# STM32H7S register map
File version: 1.3
CPU: CM7 r0p1, little endian, MPU, FPU, 4 interrupt priority bits
Registers are 32-bit, read-write, reset 0x0 unless marked. A register's access mark holds for its fields unless they carry their own. Offsets are from the block's base; [hi:lo] are bit positions; {n}, {i} and the like mark numbered series.

## GPIOA — General-purpose I/Os
Base 0x58020000
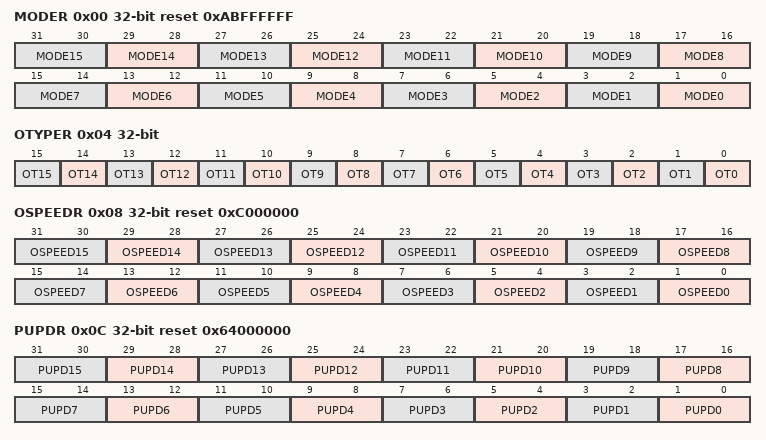
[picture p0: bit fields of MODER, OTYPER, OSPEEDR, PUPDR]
0x00 MODER reset 0xABFFFFFF — GPIO port mode register
  [2n+1:2n] MODE{n} (n=0..15) — Port x configuration pin {n}
    0=Input mode; 1=Output (General purpose output mode); 2=Alternate function mode; 3=Analog mode
0x04 OTYPER — GPIO port output type register
  [n] OT{n} (n=0..15) — Port x configuration pin {n}
    0=PushPull (Output push-pull (reset state)); 1=OpenDrain (Output open-drain)
0x08 OSPEEDR reset 0xC000000 — GPIO port output speed register
  [2n+1:2n] OSPEED{n} (n=0..15) — Port x configuration pin {n}
    0=LowSpeed; 1=MediumSpeed; 2=HighSpeed; 3=VeryHighSpeed
0x0C PUPDR reset 0x64000000 — GPIO port pull-up/pull-down register
  [2n+1:2n] PUPD{n} (n=0..15) — Port x configuration pin {n}
    0=Floating (No pull-up, pull-down); 1=PullUp; 2=PullDown
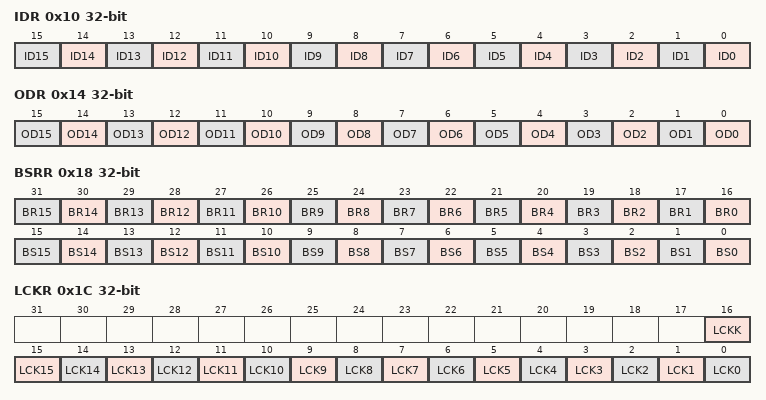
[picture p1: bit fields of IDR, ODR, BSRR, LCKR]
0x10 IDR ro (reset mask 0xFFFF0000) — GPIO port input data register
  [n] ID{n} (n=0..15) — Port input data pin {n}
    0=Low (Input is logic low); 1=High (Input is logic high)
0x14 ODR — GPIO port output data register
  [n] OD{n} (n=0..15) — Port output data pin {n}
    0=Low (Set output to logic low); 1=High (Set output to logic high)
0x18 BSRR wo — GPIO port bit set/reset register
  [n+16] BR{n} (n=0..15) — Port x reset pin {n}
    1=Resets the corresponding ODx bit
  [n] BS{n} (n=0..15) — Port x set pin {n}
    1=Set (Sets the corresponding ODx bit)
0x1C LCKR — GPIO port configuration lock register
  [16] LCKK — Lock key This bit can be read any time. It can only be modified using the lock key write sequence. - LOCK key write sequence: WR LCKR[16] = 1 + LCKR[15:0] WR LCKR[16] = 0 + LCKR[15:0] WR LCKR[16] = 1 + LCKR[15:0] - LOCK key read RD LCKR[16] = 1 (this read operation is optional but it confirms that the lock is active) Note: During the LOCK key write sequence, the value of LCK[15:0] must not change. Note: Any error in the lock sequence aborts the LOCK. Note: After the first LOCK sequence on any bit of the port, any read access on the LCKK bit returns 1 until the next MCU reset or peripheral reset.
    0=NotActive (Port configuration lock key not active); 1=Active (Port configuration lock key active)
  [n] LCK{n} (n=0..15) — Port x lock pin {n}
    0=Unlocked (Port configuration not locked); 1=Locked (Port configuration locked)
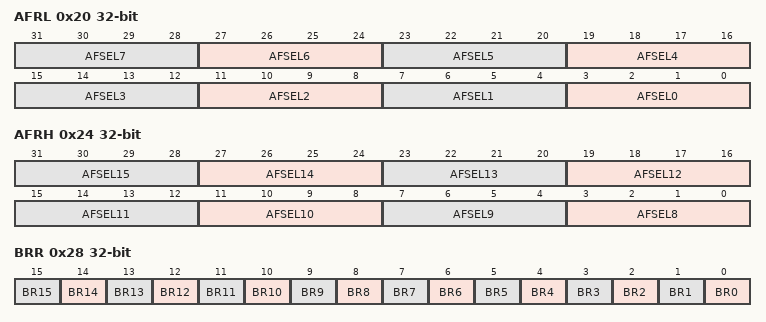
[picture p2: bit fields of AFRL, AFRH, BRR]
0x20 AFRL — GPIO alternate function low register
  [4n+3:4n] AFSEL{n} (n=0..7) — Alternate function selection for port x I/O pin y These bits are written by software to configure alternate function I/Os. Note: The bitfield is reserved and must be kept to reset value when the corresponding I/O is not available on the selected package.
    {v}=AF{v} (v=0..15)
0x24 AFRH — GPIO alternate function high register
  [4n-29:4n-32] AFSEL{n} (n=8..15) — Alternate function selection for port x I/O pin y These bits are written by software to configure alternate function I/Os. Note: The bitfield is reserved and must be kept to reset value when the corresponding I/O is not available on the selected package.
    {v}=AF{v} (v=0..15)
0x28 BRR wo — GPIO port bit reset register
  [n] BR{n} (n=0..15) — Port x reset pin {n}
    0=No action on the corresponding ODx bit; 1=Reset the ODx bit

## GPIOC — General-purpose I/Os
Base 0x58020800
Same registers: GPIOD 0x58020C00, GPIOE 0x58021000, GPIOF 0x58021400, GPIOG 0x58021800, GPIOH 0x58021C00, GPIOM 0x58023000, GPION 0x58023400, GPIOO 0x58023800, GPIOP 0x58023C00
Registers as GPIOA; these are added or differ:
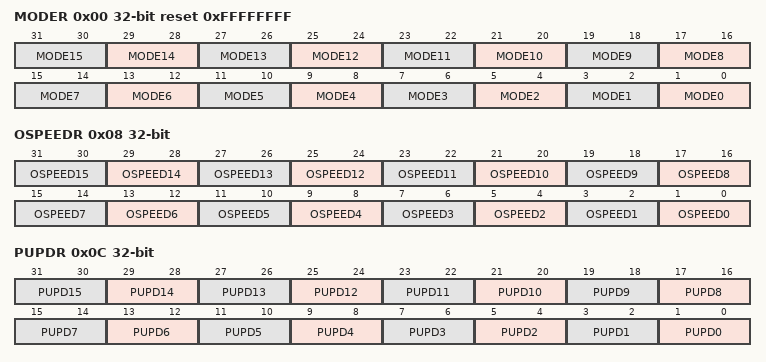
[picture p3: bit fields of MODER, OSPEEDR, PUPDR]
0x00 MODER reset 0xFFFFFFFF — GPIO port mode register
  [2n+1:2n] MODE{n} (n=0..15) — Port x configuration pin {n}
    0=Input mode; 1=Output (General purpose output mode); 2=Alternate function mode; 3=Analog mode
0x08 OSPEEDR — GPIO port output speed register
  [2n+1:2n] OSPEED{n} (n=0..15) — Port x configuration pin {n}
    0=LowSpeed; 1=MediumSpeed; 2=HighSpeed; 3=VeryHighSpeed
0x0C PUPDR — GPIO port pull-up/pull-down register
  [2n+1:2n] PUPD{n} (n=0..15) — Port x configuration pin {n}
    0=Floating (No pull-up, pull-down); 1=PullUp; 2=PullDown

## GPIOB — General-purpose I/Os
Base 0x58020400
Registers as GPIOA; these are added or differ:
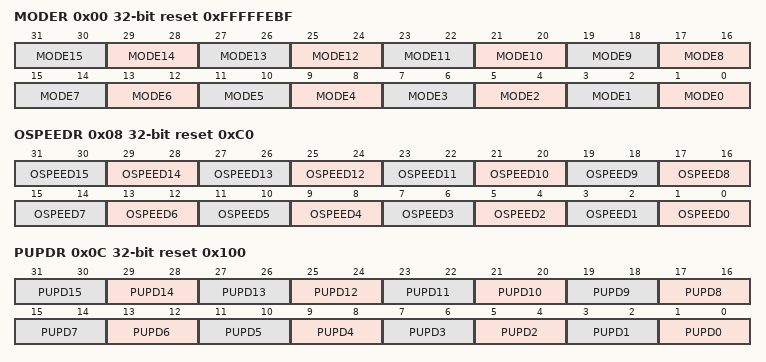
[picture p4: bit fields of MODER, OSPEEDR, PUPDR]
0x00 MODER reset 0xFFFFFEBF — GPIO port mode register
  [2n+1:2n] MODE{n} (n=0..15) — Port x configuration pin {n}
    0=Input mode; 1=Output (General purpose output mode); 2=Alternate function mode; 3=Analog mode
0x08 OSPEEDR reset 0xC0 — GPIO port output speed register
  [2n+1:2n] OSPEED{n} (n=0..15) — Port x configuration pin {n}
    0=LowSpeed; 1=MediumSpeed; 2=HighSpeed; 3=VeryHighSpeed
0x0C PUPDR reset 0x100 — GPIO port pull-up/pull-down register
  [2n+1:2n] PUPD{n} (n=0..15) — Port x configuration pin {n}
    0=Floating (No pull-up, pull-down); 1=PullUp; 2=PullDown
